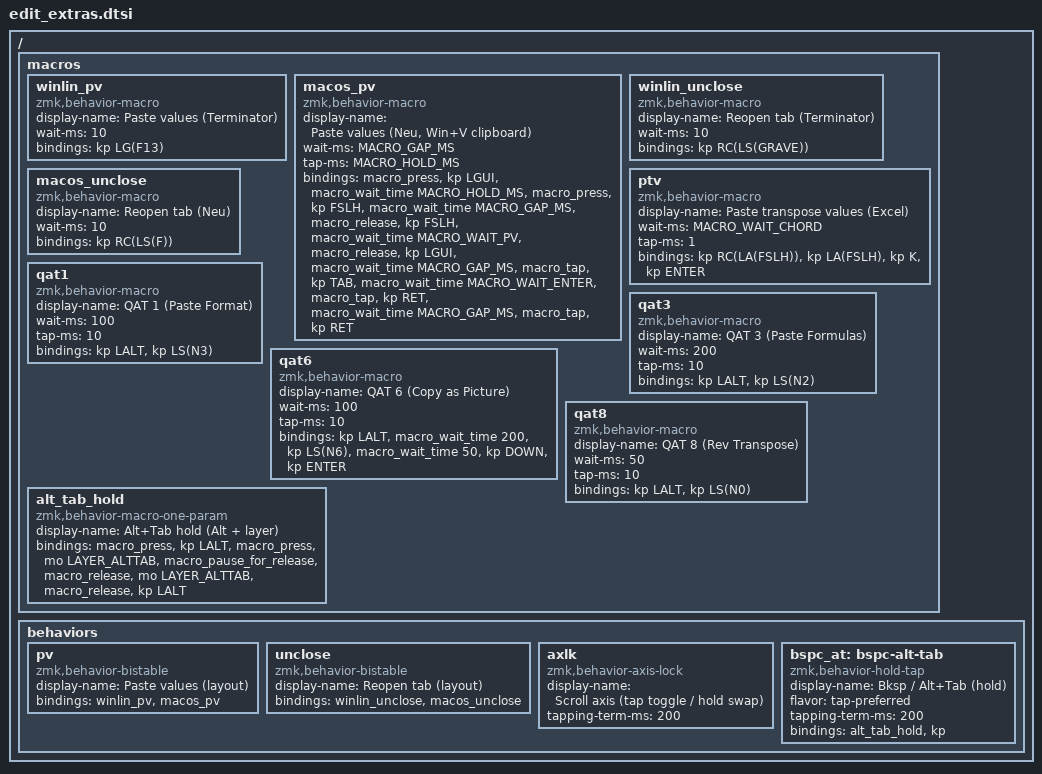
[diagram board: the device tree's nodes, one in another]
/*
 * Extra layout-aware (bistable) shortcuts for the Edit layer.
 *
 * Same idea as clipboard_layouts.dtsi: slot 0 = Terminator (kbdterm),
 * slot 1 = Neu (kbdneu); `bst_tog` flips both. All use Right Ctrl (Neu remaps
 * Left Ctrl).
 *
 * paste-values:
 *   Terminator -> Win+F13 (dacman)              : LG(F13)
 *   Neu        -> Win+V, wait 200, Tab, Enter, wait 400, Enter
 *                V is physical "/" (FSLH) on Neu.
 *                &macro_wait_time does not pause where it is written; it
 *                sets the delay after the next queued press/release. Post-Win
 *                pause armed on Win release; Enter-Enter pause on first Enter.
 *                Calibrated: E400@W200 (and slower) pasted values; E390@W500
 *                flaked; W100/W150 were false positives (normal paste). Hold
 *                MACRO_HOLD_MS; other gaps ≥ MACRO_GAP_MS.
 *
 * Excel QAT: quick Alt tap, then a per-key wait, then Shift+digit.
 *   Paste format (1)     100ms
 *   Paste formulas (3)   200ms
 *   Copy as picture (6)  100ms, then 200ms, Down, Enter
 *   Rev transpose (8)     50ms
 *
 * Neu/Terminator remap the number row (base=symbols, Shift=digits), and the
 * digit VKs are NOT on the US-QWERTY positions. ZMK N1..N0 are physical
 * scancodes; under both layouts the digit VKs sit at:
 *   1@N3  2@N7  3@N2  4@N9  5@N4  6@N6  7@N5  8@N0  9@N1  0@N8
 * So QAT 1/3/6/8 tap LS(N3)/LS(N2)/LS(N6)/LS(N0). Using LS(N1)/LS(N3)/LS(N8)
 * sent digits 9/1/0 — Excel keytips showed "00" for rev transpose.
 *
 * Both layouts mark Shift+Alt as an invalid shift state. A Shift+Alt+N6
 * chord never yields digit 6: AHK names that key ")" because Neu's unshifted
 * glyph for VK 6 (scancode 0x07) is ")". Alt must be released before Shift+N6.
 * After that digit, wait 200ms for the Copy Picture dialog, then Down, Enter.
 *
 * Paste & transpose values: same as zmk-config `m_paste_transp`.
 */

#define MACRO_WAIT_CHORD 40
#define MACRO_WAIT_PV    200
#define MACRO_WAIT_ENTER 400
#define MACRO_HOLD_MS    12
#define MACRO_GAP_MS     50

/ {
	macros {
		winlin_pv: winlin_pv {
			compatible = "zmk,behavior-macro";
			display-name = "Paste values (Terminator)";
			#binding-cells = <0>;
			wait-ms = <10>;
			bindings = <&kp LG(F13)>;
		};
		macos_pv: macos_pv {
			compatible = "zmk,behavior-macro";
			display-name = "Paste values (Neu, Win+V clipboard)";
			#binding-cells = <0>;
			wait-ms = <MACRO_GAP_MS>;
			tap-ms = <MACRO_HOLD_MS>;
			bindings
				= <&macro_press &kp LGUI>
				, <&macro_wait_time MACRO_HOLD_MS>
				, <&macro_press &kp FSLH>
				, <&macro_wait_time MACRO_GAP_MS>
				, <&macro_release &kp FSLH>
				, <&macro_wait_time MACRO_WAIT_PV>
				, <&macro_release &kp LGUI>
				, <&macro_wait_time MACRO_GAP_MS>
				, <&macro_tap &kp TAB>
				, <&macro_wait_time MACRO_WAIT_ENTER>
				, <&macro_tap &kp RET>
				, <&macro_wait_time MACRO_GAP_MS>
				, <&macro_tap &kp RET>;
		};

		winlin_unclose: winlin_unclose {
			compatible = "zmk,behavior-macro";
			display-name = "Reopen tab (Terminator)";
			#binding-cells = <0>;
			wait-ms = <10>;
			bindings = <&kp RC(LS(GRAVE))>;
		};
		macos_unclose: macos_unclose {
			compatible = "zmk,behavior-macro";
			display-name = "Reopen tab (Neu)";
			#binding-cells = <0>;
			wait-ms = <10>;
			bindings = <&kp RC(LS(F))>;
		};

		/* Same as zmk-config m_paste_transp on the numpad layer. */
		ptv: ptv {
			compatible = "zmk,behavior-macro";
			display-name = "Paste transpose values (Excel)";
			#binding-cells = <0>;
			wait-ms = <MACRO_WAIT_CHORD>;
			tap-ms = <1>;
			bindings = <&kp RC(LA(FSLH)) &kp LA(FSLH) &kp K &kp ENTER>;
		};

		/* Quick Alt tap, then the per-key wait, then Shift+digit.
		 * tap-ms is the Alt hold. wait-ms is the gap after Alt is released
		 * (ZMK attaches that delay to the key, not to a following macro_wait_time).
		 * Digit bindings use the physical keys that produce 1/3/6/8 under Neu/Term
		 * (see file header). QAT 6 is LS(N6). 1/3/8 are not US-QWERTY N1/N3/N8.
		 */
		qat1: qat1 {
			compatible = "zmk,behavior-macro";
			display-name = "QAT 1 (Paste Format)";
			#binding-cells = <0>;
			wait-ms = <100>;
			tap-ms = <10>;
			bindings = <&kp LALT &kp LS(N3)>;
		};
		qat3: qat3 {
			compatible = "zmk,behavior-macro";
			display-name = "QAT 3 (Paste Formulas)";
			#binding-cells = <0>;
			wait-ms = <200>;
			tap-ms = <10>;
			bindings = <&kp LALT &kp LS(N2)>;
		};
		/* Alt, 100ms, Shift+6, then 200ms for the Copy Picture dialog,
		 * Down, 50ms, Enter. macro_wait_time sets the delay after the
		 * next key's release, so the dialog pause is armed on LS(N6).
		 */
		qat6: qat6 {
			compatible = "zmk,behavior-macro";
			display-name = "QAT 6 (Copy as Picture)";
			#binding-cells = <0>;
			wait-ms = <100>;
			tap-ms = <10>;
			bindings
				= <&kp LALT>
				, <&macro_wait_time 200>
				, <&kp LS(N6)>
				, <&macro_wait_time 50>
				, <&kp DOWN &kp ENTER>;
		};
		qat8: qat8 {
			compatible = "zmk,behavior-macro";
			display-name = "QAT 8 (Rev Transpose)";
			#binding-cells = <0>;
			wait-ms = <50>;
			tap-ms = <10>;
			bindings = <&kp LALT &kp LS(N0)>;
		};

		/* Hold: Alt down + momentary Alt+Tab layer (left encoder → Tab / Shift+Tab).
		 * Release: layer off, then Alt up. Bound via &bspc_at on Edit Bksp.
		 * One-param (dummy) so hold-tap can be #binding-cells = <2> (macro 1 + kp 1).
		 * Layer is hardcoded — do not forward the param into &mo (ZMK param leak). */
		alt_tab_hold: alt_tab_hold {
			compatible = "zmk,behavior-macro-one-param";
			display-name = "Alt+Tab hold (Alt + layer)";
			#binding-cells = <1>;
			bindings
				= <&macro_press &kp LALT>
				, <&macro_press &mo LAYER_ALTTAB>
				, <&macro_pause_for_release>
				, <&macro_release &mo LAYER_ALTTAB>
				, <&macro_release &kp LALT>;
		};
	};

	behaviors {
		pv: pv {
			compatible = "zmk,behavior-bistable";
			display-name = "Paste values (layout)";
			#binding-cells = <0>;
			bindings = <&winlin_pv>, <&macos_pv>;
		};
		unclose: unclose {
			compatible = "zmk,behavior-bistable";
			display-name = "Reopen tab (layout)";
			#binding-cells = <0>;
			bindings = <&winlin_unclose>, <&macos_unclose>;
		};

		axlk: axlk {
			compatible = "zmk,behavior-axis-lock";
			display-name = "Scroll axis (tap toggle / hold swap)";
			#binding-cells = <0>;
			tapping-term-ms = <200>;
		};

		/* Tap = Backspace; hold = Alt + LAYER_ALTTAB until release.
		 * hold-tap requires #binding-cells = <2> (const in ZMK). */
		bspc_at: bspc-alt-tab {
			compatible = "zmk,behavior-hold-tap";
			display-name = "Bksp / Alt+Tab (hold)";
			#binding-cells = <2>;
			flavor = "tap-preferred";
			tapping-term-ms = <200>;
			bindings = <&alt_tab_hold>, <&kp>;
		};
	};
};
